# MKW36Z4 register map
Vendor: NXP Semiconductors; Series: Kinetis_W; File version: 1.6
CPU: CM0PLUS r0p0, little endian, no MPU, no FPU, VTOR, 2 interrupt priority bits
Registers are 16-bit, read-write, no defined reset value unless marked. A register's access mark holds for its fields unless they carry their own. Offsets are from the block's base; [hi:lo] are bit positions; {n}, {i} and the like mark numbered series.

## GENFSK — GENERIC FSK
Base 0x4005F000
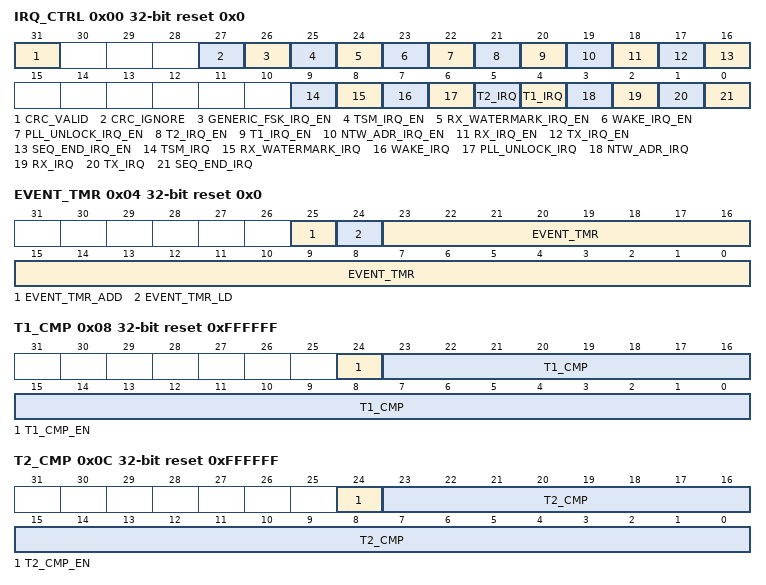
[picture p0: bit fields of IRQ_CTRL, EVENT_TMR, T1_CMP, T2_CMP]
0x00 IRQ_CTRL 32-bit reset 0x0 (reset mask 0x7FFFFC00) — IRQ CONTROL
  [31] CRC_VALID ro
    0=CRC of RX packet is not valid; 1=CRC of RX packet is valid
  [27] CRC_IGNORE
    0=RX_IRQ will not be asserted for a received packet which fails CRC verification; 1=RX_IRQ will be asserted even for a received packet which fails CRC verification
  [26] GENERIC_FSK_IRQ_EN — GENERIC_FSK_IRQ Master Enable
    0=All GENERIC_FSK Interrupts are disabled; 1=All GENERIC_FSK Interrupts can be enabled
  [25] TSM_IRQ_EN — TSM_IRQ Enable
    0=TSM Interrupt is not enabled; 1=TSM Interrupt is enabled
  [24] RX_WATERMARK_IRQ_EN — RX_WATERMARK_IRQ Enable
    0=RX Watermark Interrupt is not enabled; 1=RX Watermark Interrupt is enabled
  [23] WAKE_IRQ_EN — WAKE_IRQ Enable
    0=Wake Interrupt is not enabled; 1=Wake Interrupt is enabled
  [22] PLL_UNLOCK_IRQ_EN — PLL_UNLOCK_IRQ Enable
    0=PLL Unlock Interrupt is not enabled; 1=PLL Unlock Interrupt is enabled
  [21] T2_IRQ_EN — T2_IRQ Enable
    0=Timer1 (T2) Compare Interrupt is not enabled; 1=Timer1 (T2) Compare Interrupt is enabled
  [20] T1_IRQ_EN — T1_IRQ Enable
    0=Timer1 (T1) Compare Interrupt is not enabled; 1=Timer1 (T1) Compare Interrupt is enabled
  [19] NTW_ADR_IRQ_EN — NTW_ADR_IRQ Enable
    0=Network Address Match Interrupt is not enabled; 1=Network Address Match Interrupt is enabled
  [18] RX_IRQ_EN — RX_IRQ Enable
    0=RX Interrupt is not enabled; 1=RX Interrupt is enabled
  [17] TX_IRQ_EN — TX_IRQ Enable
    0=TX Interrupt is not enabled; 1=TX Interrupt is enabled
  [16] SEQ_END_IRQ_EN — SEQ_END_IRQ Enable
    0=Sequence End Interrupt is not enabled; 1=Sequence End Interrupt is enabled
  [9] TSM_IRQ ro — TSM Interrupt
    0=TSM0_IRQ and TSM1_IRQ are both clear; 1=Indicates TSM0_IRQ or TSM1_IRQ is set in XCVR_STATUS
  [8] RX_WATERMARK_IRQ — RX Watermark Interrupt
    0=RX Watermark Interrupt is not asserted; 1=RX Watermark Interrupt is asserted
  [7] WAKE_IRQ — Wake Interrrupt
    0=Wake Interrupt is not asserted; 1=Wake Interrupt is asserted
  [6] PLL_UNLOCK_IRQ — PLL Unlock Interrupt
    0=PLL Unlock Interrupt is not asserted; 1=PLL Unlock Interrupt is asserted
  [5] T2_IRQ — Timer2 (T2) Compare Interrupt
    0=Timer2 (T2) Compare Interrupt is not asserted; 1=Timer2 (T2) Compare Interrupt is asserted
  [4] T1_IRQ — Timer1 (T1) Compare Interrupt
    0=Timer1 (T1) Compare Interrupt is not asserted; 1=Timer1 (T1) Compare Interrupt is asserted
  [3] NTW_ADR_IRQ — Network Address Match Interrupt
    0=Network Address Match Interrupt is not asserted; 1=Network Address Match Interrupt is asserted
  [2] RX_IRQ — RX Interrupt
    0=RX Interrupt is not asserted; 1=RX Interrupt is asserted
  [1] TX_IRQ — TX Interrupt
    0=TX Interrupt is not asserted; 1=TX Interrupt is asserted
  [0] SEQ_END_IRQ — Sequence End Interrupt
    0=Sequence End Interrupt is not asserted; 1=Sequence End Interrupt is asserted
0x04 EVENT_TMR 32-bit reset 0x0 (reset mask 0xFF000000) — EVENT TIMER
  [25] EVENT_TMR_ADD wo — Event Timer Add
  [24] EVENT_TMR_LD wo — Event Timer Load
  [23:0] EVENT_TMR — Event Timer
0x08 T1_CMP 32-bit reset 0xFFFFFF — T1 COMPARE
  [24] T1_CMP_EN — Timer1 (T1) Compare Enable
  [23:0] T1_CMP — Timer1 (T1) Compare Value
0x0C T2_CMP 32-bit reset 0xFFFFFF — T2 COMPARE
  [24] T2_CMP_EN — Timer2 (T2) Compare Enable
  [23:0] T2_CMP — Timer2 (T2) Compare Value
0x10 TIMESTAMP 32-bit ro reset 0x0 (reset mask 0xFF000000)
  [23:0] TIMESTAMP — Received Packet Timestamp
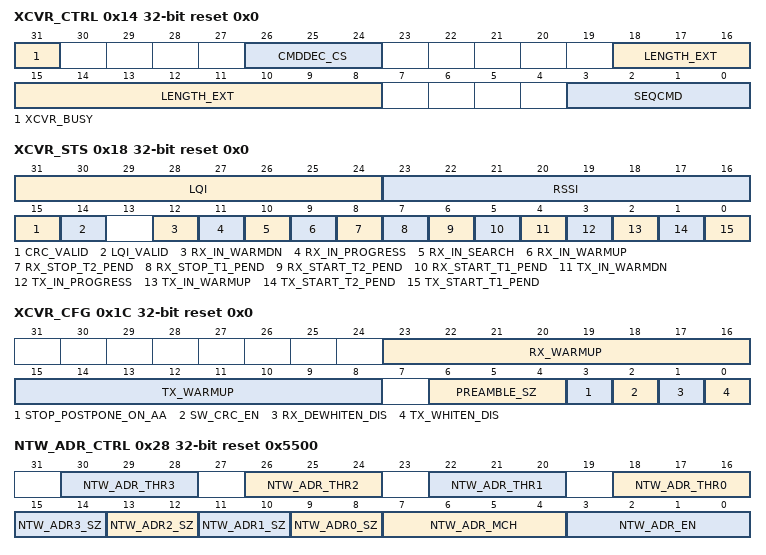
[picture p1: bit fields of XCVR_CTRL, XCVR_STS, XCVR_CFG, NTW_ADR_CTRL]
0x14 XCVR_CTRL 32-bit reset 0x0 (reset mask 0x78F800FF) — TRANSCEIVER CONTROL
  [31] XCVR_BUSY ro — Transceiver Busy
    0=IDLE; 1=BUSY
  [26:24] CMDDEC_CS ro — Command Decode
  [18:8] LENGTH_EXT ro — Extracted Length Field
  [3:0] SEQCMD — Sequence Commands
    0=No Action; 1=TX Start Now; 2=TX Start @ T1 Timer Compare Match (EVENT_TMR = T1_CMP); 3=TX Start @ T2 Timer Compare Match (EVENT_TMR = T2_CMP); 4=TX Cancel -- Cancels pending TX events but do not abort a TX-in-progress; 5=RX Start Now; 6=RX Start @ T1 Timer Compare Match (EVENT_TMR = T1_CMP); 7=RX Start @ T2 Timer Compare Match (EVENT_TMR = T2_CMP); 8=RX Stop @ T1 Timer Compare Match (EVENT_TMR = T1_CMP); 9=RX Stop @ T2 Timer Compare Match (EVENT_TMR = T2_CMP); 10=RX Cancel -- Cancels pending RX events but do not abort a RX-in-progress; 11=Abort All - Cancels all pending events and abort any sequence-in-progress
0x18 XCVR_STS 32-bit ro reset 0x0 (reset mask 0x2000) — TRANSCEIVER STATUS
  [31:24] LQI — Link Quality Indicator
  [23:16] RSSI — Received Signal Stength Indicator, in dBm
  [15] CRC_VALID — CRC Valid Indicator
    0=CRC is not valid for RX packet; 1=CRC is valid for RX packet
  [14] LQI_VALID — LQI Valid Indicator
    0=LQI is not yet valid for RX packet; 1=LQI is valid for RX packet
  [12] RX_IN_WARMDN — RX Warmdown Status
  [11] RX_IN_PROGRESS — RX in Progress Status
  [10] RX_IN_SEARCH — RX Search Status
  [9] RX_IN_WARMUP — RX Warmup Status
  [8] RX_STOP_T2_PEND — RX T2 Start Pending Status
  [7] RX_STOP_T1_PEND — RX T1 Stop Pending Status
  [6] RX_START_T2_PEND — RX T2 Start Pending Status
  [5] RX_START_T1_PEND — RX T1 Start Pending Status
  [4] TX_IN_WARMDN — TX Warmdown Status
  [3] TX_IN_PROGRESS — TX in Progress Status
  [2] TX_IN_WARMUP — TX Warmup Status
  [1] TX_START_T2_PEND — TX T2 Start Pending Status
  [0] TX_START_T1_PEND — TX T1 Start Pending Status
0x1C XCVR_CFG 32-bit reset 0x0 (reset mask 0xFF0000FF) — TRANSCEIVER CONFIGURATION
  [23:16] RX_WARMUP ro — Receive Warmup Time
  [15:8] TX_WARMUP ro — Transmit Warmup Time
  [6:4] PREAMBLE_SZ — Preamble Size
  [3] STOP_POSTPONE_ON_AA — Postpone Stop Command Timeout On Access Address Match Enable
    0=STOP Abort will occur on RX_STOP_T1 or RX_STOP_T1 Event Timer match, regardless of ntw_adr_matched; 1=STOP Abort will be deferred on RX_STOP_T1 or RX_STOP_T1 Event Timer match, if ntw_adr_matched is asserted; otherwise the RX_STOP Abort will occur immediately
  [2] SW_CRC_EN — Software CRC Enable
  [1] RX_DEWHITEN_DIS — RX De-Whitening Disable
  [0] TX_WHITEN_DIS — TX Whitening Disable
0x20 CHANNEL_NUM 32-bit reset 0x0 — CHANNEL NUMBER
  [6:0] CHANNEL_NUM — Channel Number
0x24 TX_POWER 32-bit reset 0x0 — TRANSMIT POWER
  [5:0] TX_POWER — Transmit Power
0x28 NTW_ADR_CTRL 32-bit reset 0x5500 (reset mask 0xFFFFFF0F) — NETWORK ADDRESS CONTROL
  [4n+18:4n+16] NTW_ADR_THR{n} (n=0..3) — Network Address {n} Threshold
  [2n+9:2n+8] NTW_ADR{n}_SZ (n=0..3) — Network Address {n} Size
    0=Network Address {n} requires a 8-bit correlation; 1=Network Address {n} requires a 16-bit correlation; 2=Network Address {n} requires a 24-bit correlation; 3=Network Address {n} requires a 32-bit correlation
  [7:4] NTW_ADR_MCH ro — Network Address Match
    1=Network Address 0 has matched; 2=Network Address 1 has matched; 4=Network Address 2 has matched; 8=Network Address 3 has matched
  [3:0] NTW_ADR_EN — Network Address Enable
    1=Enable Network Address 0 for correlation; 2=Enable Network Address 1 for correlation; 4=Enable Network Address 2 for correlation; 8=Enable Network Address 3 for correlation
{0x2C+4i} NTW_ADR_{i} 32-bit reset 0x55555555 (i=0..2) — NETWORK ADDRESS {i}
  [31:0] NTW_ADR_{i} — Network Address {i}
0x38 NTW_ADR_3 32-bit reset 0x55555555 — NETWORK ADDRESS 3
  [31:0] NTW_ADR_3 — Network Address 2
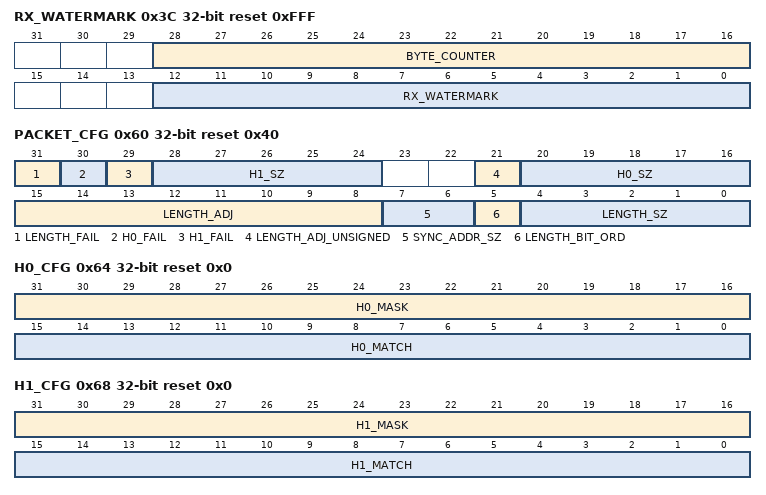
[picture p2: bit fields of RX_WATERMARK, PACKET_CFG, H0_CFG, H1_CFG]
0x3C RX_WATERMARK 32-bit reset 0xFFF (reset mask 0xE000FFFF) — RECEIVE WATERMARK
  [28:16] BYTE_COUNTER ro
  [12:0] RX_WATERMARK — Receive Watermark
0x40 DSM_CTRL 32-bit reset 0x0 — DSM CONTROL
  [0] GEN_SLEEP_REQUEST — GENERIC_FSK Deep Sleep Mode Request
0x44 PART_ID 32-bit ro reset 0x1
  [7:0] PART_ID
0x60 PACKET_CFG 32-bit reset 0x40 (reset mask 0x1FFFFFFF) — PACKET CONFIGURATION
  [31] LENGTH_FAIL ro — Maximum Length Violated Status Bit
  [30] H0_FAIL ro — H0 Violated Status Bit
  [29] H1_FAIL ro — H1 Violated Status Bit
  [28:24] H1_SZ — H1 Size
  [21] LENGTH_ADJ_UNSIGNED — Length Adjustment Unsigned Enabled
    0=Hardware interprets LENGTH_ADJ as a signed integer (default); 1=Hardware interprets LENGTH_ADJ as a unsigned integer
  [20:16] H0_SZ — H0 Size
  [15:8] LENGTH_ADJ — Length Adjustment
  [7:6] SYNC_ADDR_SZ — Sync Address Size
  [5] LENGTH_BIT_ORD — LENGTH Bit Order
    0=LS Bit First; 1=MS Bit First
  [4:0] LENGTH_SZ — LENGTH Size
0x64 H0_CFG 32-bit reset 0x0 — H0 CONFIGURATION
  [31:16] H0_MASK, [15:0] H0_MATCH
0x68 H1_CFG 32-bit reset 0x0 — H1 CONFIGURATION
  [31:16] H1_MASK, [15:0] H1_MATCH
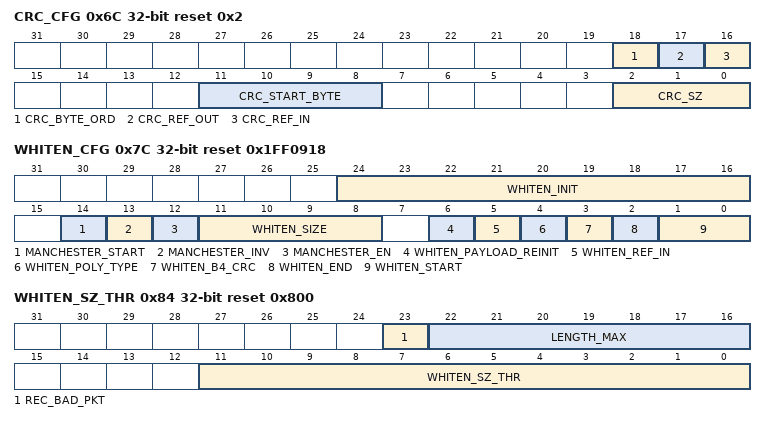
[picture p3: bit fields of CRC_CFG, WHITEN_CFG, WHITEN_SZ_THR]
0x6C CRC_CFG 32-bit reset 0x2 — CRC CONFIGURATION
  [18] CRC_BYTE_ORD — CRC Byte Order
    0=LS Byte First; 1=MS Byte First
  [17] CRC_REF_OUT — CRC Reflect Out
    0=do not manipulate CRC result; 1=CRC result is to be reflected bitwise (operated on entire word)
  [16] CRC_REF_IN — CRC Reflect In
    0=do not manipulate input data stream; 1=reflect each byte in the input stream bitwise
  [11:8] CRC_START_BYTE — Configure CRC Start Point
  [2:0] CRC_SZ — CRC Size (in octets)
0x70 CRC_INIT 32-bit reset 0x0 — CRC INITIALIZATION
  [31:0] CRC_SEED — CRC Seed Value
0x74 CRC_POLY 32-bit reset 0x10210000 — CRC POLYNOMIAL
  [31:0] CRC_POLY — CRC Polynomial.
0x78 CRC_XOR_OUT 32-bit reset 0x0
0x7C WHITEN_CFG 32-bit reset 0x1FF0918 — WHITENER CONFIGURATION
  [24:16] WHITEN_INIT — Initialization Value for Whitening/De-whitening
  [14] MANCHESTER_START — Configure Manchester Encoding Start Point
    0=Start Manchester coding at start-of-payload; 1=Start Manchester coding at start-of-header
  [13] MANCHESTER_INV — Configure for Inverted Manchester Encoding
    0=Manchester coding as per 802.3; 1=Manchester coding as per 802.3 but with the encoding signal inverted
  [12] MANCHESTER_EN — Configure for Manchester Encoding/Decoding
    0=Disable Manchester encoding (TX) and decoding (RX); 1=Enable Manchester encoding (TX) and decoding (RX)
  [11:8] WHITEN_SIZE — Length of Whitener LFSR
  [6] WHITEN_PAYLOAD_REINIT — Configure for Whitener re-initialization
    0=Don't re-initialize Whitener LFSR at start-of-payload; 1=Re-initialize Whitener LFSR at start-of-payload
  [5] WHITEN_REF_IN — Whiten Reflect Input
  [4] WHITEN_POLY_TYPE — Whiten Polynomial Type
  [3] WHITEN_B4_CRC — Congifure for Whitening-before-CRC
    0=CRC before whiten/de-whiten; 1=Whiten/de-whiten before CRC
  [2] WHITEN_END — Configure end-of-whitening
    0=end whiten at end-of-payload; 1=end whiten at end-of-crc
  [1:0] WHITEN_START — Configure Whitener Start Point
    0=no whitening; 1=start whitening at start-of-H0; 2=start whitening at start-of-H1 but only if LENGTH > WHITEN_SZ_THR; 3=start whitening at start-of-payload but only if LENGTH > WHITEN_SZ_THR
0x80 WHITEN_POLY 32-bit reset 0x21 — WHITENER POLYNOMIAL
  [8:0] WHITEN_POLY — Whitener Polynomial
0x84 WHITEN_SZ_THR 32-bit reset 0x800 — WHITENER SIZE THRESHOLD
  [23] REC_BAD_PKT — Receive Bad Packets
    0=packets which fail H0, H1, or LENGTH_MAX result in an automatic recycle after the header is received and parsed; 1=packets which fail H0, H1, or LENGTH_MAX are received in their entirety
  [22:16] LENGTH_MAX — Maximum Length for Received Packets
  [11:0] WHITEN_SZ_THR — Whitener Size Threshold
0x88 BITRATE 32-bit reset 0x0
  [1:0] BITRATE
    0=1Mbit/sec; 1=500Kbit/sec; 2=250Kbit/sec (not supported if WHITEN_CFG[MANCHESTER_EN]=1)
0x8C PB_PARTITION 32-bit reset 0x220 — PACKET BUFFER PARTITION POINT
  [10:0] PB_PARTITION — Packet Buffer Partition Point
{0x700+2i} PACKET_BUFFER_{i} (i=0..1087) — PACKET BUFFER
  [15:0] PACKET_BUFFER — PACKET BUFFER RAM
